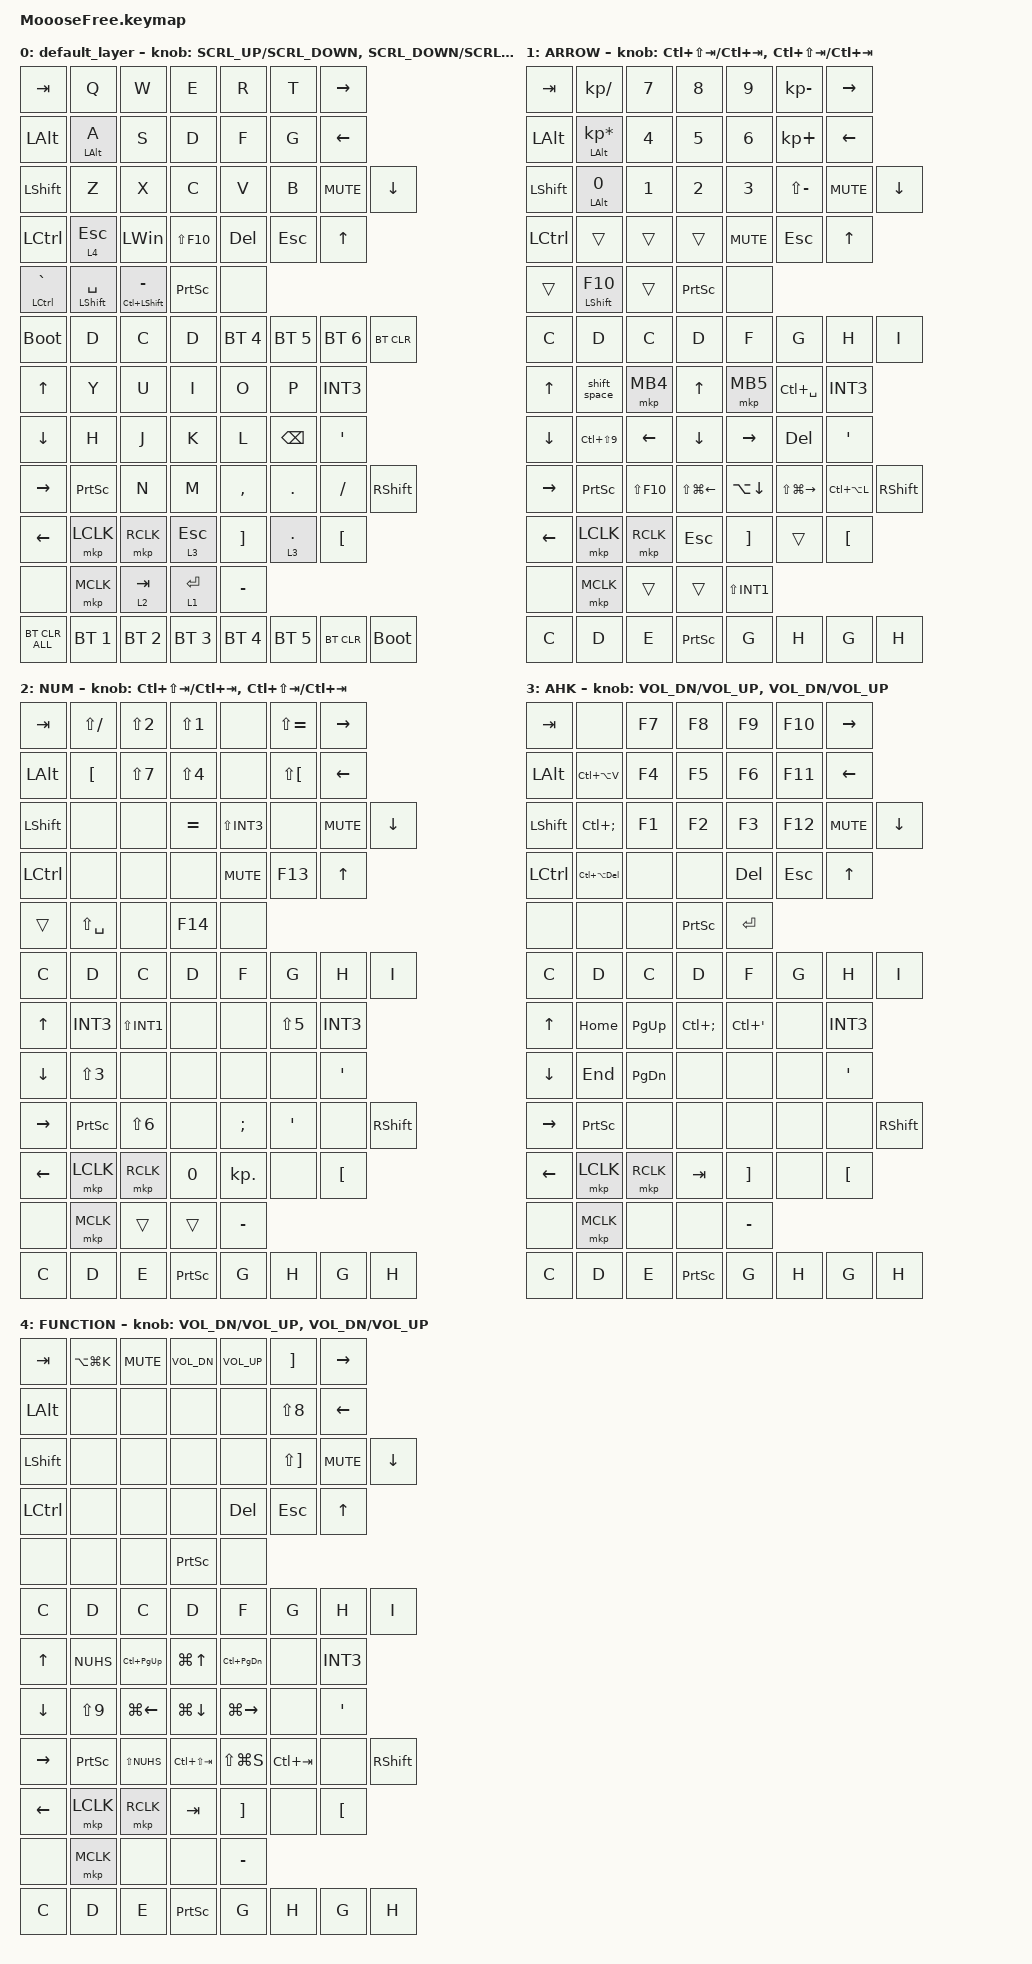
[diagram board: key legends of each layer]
#include <dt-bindings/zmk/mouse.h>
#include <behaviors/rgbled_widget.dtsi>
#include <zephyr/dt-bindings/input/input-event-codes.h>
#include <behaviors.dtsi>
#include <dt-bindings/zmk/bt.h>
#include <dt-bindings/zmk/keys.h>
#include <dt-bindings/zmk/pointing.h>

#define ZMK_POINTING_DEFAULT_SCRL_VAL 100

// Leyer

#define ARROW 1
#define NUM 2
#define AHK 3
#define FUNCTION 4

// Japanese key definitions (reference only)
// JP_MINUS  = MINUS        // -
// JP_CARET  = EQUAL        // ^
// JP_YEN    = INT3         // ¥
// JP_AT     = LBKT         // @
// JP_LBKT   = RBKT         // [
// JP_EISU   = CAPS         // Eisu (英数)
// JP_SEMI   = SEMI         // ;
// JP_COLON  = SQT          // :
// JP_RBKT   = NUHS         // ]
// JP_COMMA  = COMMA        // ,
// JP_DOT    = DOT          // .
// JP_SLASH  = SLASH        // /
// JP_BSLH   = INT1         // (backslash)
// JP_MHEN   = INT5         // Muhenkan (無変換)
// JP_HENK   = INT4         // Henkan (変換)
// JP_EXCL   = LS(N1)       // !
// JP_DQT    = LS(N2)       // "
// JP_HASH   = LS(N3)       // #
// JP_DLLR   = LS(N4)       // $
// JP_PRCNT  = LS(N5)       // %
// JP_AMPS   = LS(N6)       // &
// JP_SQT    = LS(N7)       // '
// JP_LPAR   = LS(N8)       // (
// JP_RPAR   = LS(N9)       // )
// JP_EQUAL  = LS(MINUS)    // =
// JP_TILDE  = LS(EQUAL)    // ~
// JP_PIPE   = LS(INT3)     // |
// JP_GRAVE  = LS(LBKT)     // `
// JP_LBRC   = LS(RBKT)     // {
// JP_CAPS   = LS(CAPS)     // Caps Lock
// JP_PLUS   = LS(SEMI)     // +
// JP_ASTRK  = LS(SQT)     // *
// JP_RBRC   = LS(NUHS)    // }
// JP_LT     = LS(COMMA)   // <
// JP_RT     = LS(DOT)     // >
// JP_QMARK  = LS(SLASH)   // ?
// JP_UNDER  = LS(INT1)    // _

&mt {
    flavor = "hold-preferred";
    tapping-term-ms = <220>;
    quick-tap-ms = <120>;
};

&lt {
    flavor = "hold-preferred";
    tapping-term-ms = <220>;
    quick-tap-ms = <120>;
};

/ {
    macros {
        to_layer_0: to_layer_0 {
            compatible = "zmk,behavior-macro-one-param";
            #binding-cells = <1>;
            bindings = <&to 0 &macro_param_1to1 &kp MACRO_PLACEHOLDER>;
            label = "TO_LAYER_0";
        };

        my_sp: my_sp {
            compatible = "zmk,behavior-macro";
            #binding-cells = <0>;
            bindings = <&macro_tap>, <&kp INT5>, <&macro_tap>, <&kp LS(N3)>;
        };

        my_dq: my_dq {
            #binding-cells = <0>;
            compatible = "zmk,behavior-macro";
            bindings =
                <&macro_tap>,
                <&kp INT5>,
                <&macro_tap>,
                <&kp LS(N2)>,
                <&macro_tap>,
                <&kp LS(N2)>;
        };

        my_sq: my_sq {
            #binding-cells = <0>;
            compatible = "zmk,behavior-macro";
            bindings =
                <&macro_tap>,
                <&kp INT5>,
                <&macro_tap>,
                <&kp LS(N7)>,
                <&macro_tap>,
                <&kp LS(N7)>;
        };

        my_kakko: my_kakko {
            compatible = "zmk,behavior-macro";
            #binding-cells = <0>;
            bindings =
                <&macro_tap>,
                <&kp INT5>,
                <&macro_tap>,
                <&kp LS(N8)>,
                <&macro_tap>,
                <&kp LS(N9)>;
        };

        my_br: my_br {
            compatible = "zmk,behavior-macro";
            #binding-cells = <0>;
            bindings =
                <&macro_tap>,
                <&kp INT5>,
                <&macro_tap>,
                <&kp LS(COMMA)>,
                <&macro_tap>,
                <&kp B>,
                <&macro_tap>,
                <&kp R>,
                <&macro_tap>,
                <&kp LS(DOT)>;
        };

        shift_space: shift_space {
            compatible = "zmk,behavior-macro";
            #binding-cells = <0>;
            bindings = <&kp INTERNATIONAL_5 &kp LS(SPACE)>;
            label = "SHIFT_SPACE";
        };
    };

    behaviors {
        lt_to_layer_0: lt_to_layer_0 {
            compatible = "zmk,behavior-hold-tap";
            label = "LAYER_TAP_TO_0";
            bindings = <&mo>, <&to_layer_0>;

            #binding-cells = <2>;
            flavor = "hold-preferred";
            tapping-term-ms = <220>;
            quick-tap-ms = <120>;
        };

        rot_kp: sensor_rotate_kp {
            compatible = "zmk,behavior-sensor-rotate-var";
            #sensor-binding-cells = <2>;
            bindings = <&kp>, <&kp>;

            tap-ms = <20>;
        };

        rot_mkp: sensor_rotate_mkp {
            compatible = "zmk,behavior-sensor-rotate-var";
            #sensor-binding-cells = <2>;
            bindings = <&mkp>, <&mkp>;

            tap-ms = <20>;
        };

        mouse_scroll: mouse_wheel_scrl {
            compatible = "zmk,behavior-sensor-rotate-var";
            #sensor-binding-cells = <2>;
            bindings = <&msc>, <&msc>;

            tap-ms = <20>;
        };

        mouse_scroll2: mouse_wheel_scrl2 {
            compatible = "zmk,behavior-sensor-rotate-var";
            #sensor-binding-cells = <2>;
            bindings = <&msc>, <&msc>;

            tap-ms = <16>;
        };
    };

    keymap {
        compatible = "zmk,keymap";

        default_layer {
            bindings = <
&kp TAB          &kp Q             &kp W                 &kp E                 &kp R         &kp T         &kp RIGHT
&kp LALT         &mt LALT A        &kp S                 &kp D                 &kp F         &kp G         &kp LEFT
&kp LSHIFT       &kp Z             &kp X                 &kp C                 &kp V         &kp B         &kp C_MUTE    &kp DOWN
&kp LCTRL        &lt 4 ESC         &kp LWIN              &kp LS(F10)           &kp DEL       &kp ESC       &kp UP
&mt LCTRL GRAVE  &mt LSHIFT SPACE  &mt LC(LSHIFT) MINUS  &kp PSCRN             &none
&bootloader      &kp D             &kp C                 &kp D                 &bt BT_SEL 4  &bt BT_SEL 5  &bt BT_SEL 6  &bt BT_CLR
&kp UP           &kp Y             &kp U                 &kp I                 &kp O         &kp P         &kp INT3
&kp DOWN         &kp H             &kp J                 &kp K                 &kp L         &kp BSPC      &kp SQT
&kp RIGHT        &kp PSCRN         &kp N                 &kp M                 &kp COMMA     &kp DOT       &kp SLASH     &kp RSHIFT
&kp LEFT         &mkp LCLK         &mkp RCLK             &lt_to_layer_0 3 ESC  &kp RBKT      &lt 3 DOT     &kp LBKT
&none            &mkp MCLK         &lt 2 TAB             &lt 1 ENTER           &kp MINUS
&bt BT_CLR_ALL   &bt BT_SEL 1      &bt BT_SEL 2          &bt BT_SEL 3          &bt BT_SEL 4  &bt BT_SEL 5  &bt BT_CLR    &bootloader
            >;

            sensor-bindings = <&mouse_scroll2 SCRL_UP SCRL_DOWN &mouse_scroll SCRL_DOWN SCRL_UP>;
        };

        ARROW {
            bindings = <
&kp TAB     &kp KP_SLASH          &kp N7       &kp N8            &kp N9        &kp KP_MINUS       &kp RIGHT
&kp LALT    &mt LALT KP_ASTERISK  &kp N4       &kp N5            &kp N6        &kp KP_PLUS        &kp LEFT
&kp LSHIFT  &mt LALT N0           &kp N1       &kp N2            &kp N3        &kp LS(MINUS)      &kp C_MUTE     &kp DOWN
&kp LCTRL   &trans                &trans       &trans            &kp C_MUTE    &kp ESC            &kp UP
&trans      &mt LSHIFT F10        &trans       &kp PSCRN         &none
&kp C       &kp D                 &kp C        &kp D             &kp F         &kp G              &kp H          &kp I
&kp UP      &shift_space          &mkp MB4     &kp UP            &mkp MB5      &kp LC(SPACE)      &kp INT3
&kp DOWN    &kp LC(LS(N9))        &kp LEFT     &kp DOWN          &kp RIGHT     &kp DEL            &kp SQT
&kp RIGHT   &kp PSCRN             &kp LS(F10)  &kp LS(LG(LEFT))  &kp LA(DOWN)  &kp LS(LG(RIGHT))  &kp LC(LA(L))  &kp RSHIFT
&kp LEFT    &mkp LCLK             &mkp RCLK    &kp ESC           &kp RBKT      &trans             &kp LBKT
&none       &mkp MCLK             &trans       &trans            &kp LS(INT1)
&kp C       &kp D                 &kp E        &kp PSCRN         &kp G         &kp H              &kp G          &kp H
            >;

            sensor-bindings = <&inc_dec_kp LC(LS(TAB)) LC(TAB) &inc_dec_kp LC(LS(TAB)) LC(TAB)>;
        };

        NUM {
            bindings = <
&kp TAB     &kp LS(SLASH)  &kp LS(N2)    &kp LS(N1)  &none         &kp LS(EQUAL)  &kp RIGHT
&kp LALT    &kp LBKT       &kp LS(N7)    &kp LS(N4)  &none         &kp LS(LBKT)   &kp LEFT
&kp LSHIFT  &none          &none         &kp EQUAL   &kp LS(INT3)  &none          &kp C_MUTE  &kp DOWN
&kp LCTRL   &none          &none         &none       &kp C_MUTE    &kp F13        &kp UP
&trans      &kp LS(SPACE)  &none         &kp F14     &none
&kp C       &kp D          &kp C         &kp D       &kp F         &kp G          &kp H       &kp I
&kp UP      &kp INT3       &kp LS(INT1)  &none       &none         &kp LS(N5)     &kp INT3
&kp DOWN    &kp LS(N3)     &none         &none       &none         &none          &kp SQT
&kp RIGHT   &kp PSCRN      &kp LS(N6)    &none       &kp SEMI      &kp SQT        &none       &kp RSHIFT
&kp LEFT    &mkp LCLK      &mkp RCLK     &kp N0      &kp KP_DOT    &none          &kp LBKT
&none       &mkp MCLK      &trans        &trans      &kp MINUS
&kp C       &kp D          &kp E         &kp PSCRN   &kp G         &kp H          &kp G       &kp H
            >;

            sensor-bindings = <&inc_dec_kp LC(LS(TAB)) LC(TAB) &inc_dec_kp LC(LS(TAB)) LC(TAB)>;
        };

        AHK {
            bindings = <
&kp TAB     &none            &kp F7     &kp F8        &kp F9         &kp F10  &kp RIGHT
&kp LALT    &kp LC(LA(V))    &kp F4     &kp F5        &kp F6         &kp F11  &kp LEFT
&kp LSHIFT  &kp LC(SEMI)     &kp F1     &kp F2        &kp F3         &kp F12  &kp C_MUTE  &kp DOWN
&kp LCTRL   &kp LC(LA(DEL))  &none      &none         &kp DEL        &kp ESC  &kp UP
&none       &none            &none      &kp PSCRN     &kp ENTER
&kp C       &kp D            &kp C      &kp D         &kp F          &kp G    &kp H       &kp I
&kp UP      &kp HOME         &kp PG_UP  &kp LC(SEMI)  &kp LC(SQT)    &none    &kp INT3
&kp DOWN    &kp END          &kp PG_DN  &none         &none          &none    &kp SQT
&kp RIGHT   &kp PSCRN        &none      &none         &none          &none    &none       &kp RSHIFT
&kp LEFT    &mkp LCLK        &mkp RCLK  &kp TAB       &kp RBKT       &none    &kp LBKT
&none       &mkp MCLK        &none      &none         &kp MINUS
&kp C       &kp D            &kp E      &kp PSCRN     &kp G          &kp H    &kp G       &kp H
            >;

            sensor-bindings = <&inc_dec_kp C_VOL_DN C_VOL_UP &inc_dec_kp C_VOL_DN C_VOL_UP>;
        };

        FUNCTION {
            bindings = <
&kp TAB     &kp LA(LG(K))  &kp C_MUTE     &kp C_VOL_DN     &kp C_VOL_UP   &kp RBKT      &kp RIGHT
&kp LALT    &none          &none          &none            &none          &kp LS(N8)    &kp LEFT
&kp LSHIFT  &none          &none          &none            &none          &kp LS(RBKT)  &kp C_MUTE  &kp DOWN
&kp LCTRL   &none          &none          &none            &kp DEL        &kp ESC       &kp UP
&none       &none          &none          &kp PSCRN        &none
&kp C       &kp D          &kp C          &kp D            &kp F          &kp G         &kp H       &kp I
&kp UP      &kp NUHS       &kp LC(PG_UP)  &kp LG(UP)       &kp LC(PG_DN)  &none         &kp INT3
&kp DOWN    &kp LS(N9)     &kp LG(LEFT)   &kp LG(DOWN)     &kp LG(RIGHT)  &none         &kp SQT
&kp RIGHT   &kp PSCRN      &kp LS(NUHS)   &kp LC(LS(TAB))  &kp LS(LG(S))  &kp LC(TAB)   &none       &kp RSHIFT
&kp LEFT    &mkp LCLK      &mkp RCLK      &kp TAB          &kp RBKT       &none         &kp LBKT
&none       &mkp MCLK      &none          &none            &kp MINUS
&kp C       &kp D          &kp E          &kp PSCRN        &kp G          &kp H         &kp G       &kp H
            >;

            sensor-bindings = <&inc_dec_kp C_VOL_DN C_VOL_UP &inc_dec_kp C_VOL_DN C_VOL_UP>;
        };
    };
};
